# MCXC444 register map
Vendor: NXP Semiconductors; Series: MCX; File version: 1.6
CPU: CM0PLUS r0p0, little endian, no MPU, no FPU, VTOR, 2 interrupt priority bits
Registers are 32-bit, read-write, reset 0x0 unless marked. A register's access mark holds for its fields unless they carry their own. Offsets are from the block's base; [hi:lo] are bit positions; {n}, {i} and the like mark numbered series.

## GPIOA — General Purpose Input/Output
Base 0x400FF000; register names take the prefix GPIOA_
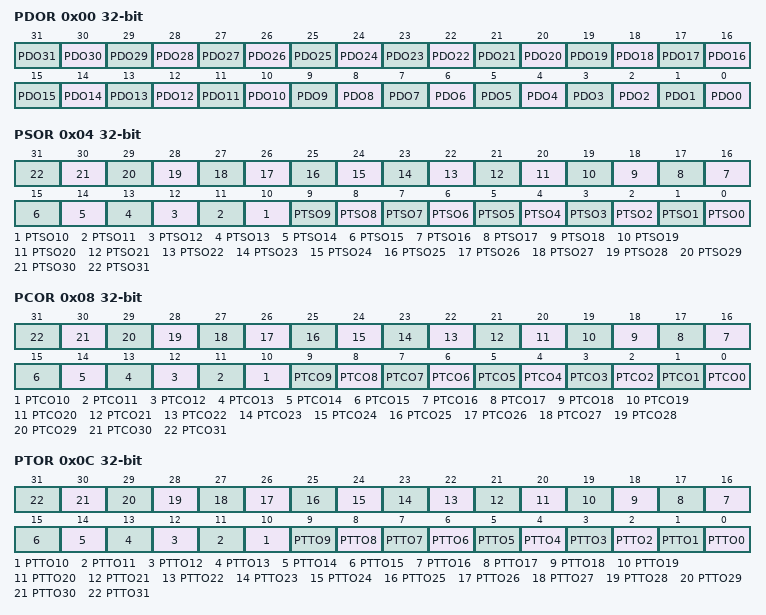
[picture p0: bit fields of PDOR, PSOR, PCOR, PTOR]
0x00 PDOR — Port Data Output Register
  [all] fields
    0=b00000000000000000000000000000000 (Logic level 0 is driven on pin, provided pin is configured for general-purpose output.); 1=b00000000000000000000000000000001 (Logic level 1 is driven on pin, provided pin is configured for general-purpose output.)
  [n] PDO{n} (n=0..31) — Port Data Output
0x04 PSOR — Port Set Output Register
  [all] fields
    0=b00000000000000000000000000000000 (Corresponding bit in PDORn does not change.); 1=b00000000000000000000000000000001 (Corresponding bit in PDORn is set to logic 1.)
  [n] PTSO{n} (n=0..31) — Port Set Output
0x08 PCOR — Port Clear Output Register
  [all] fields
    0=b00000000000000000000000000000000 (Corresponding bit in PDORn does not change.); 1=b00000000000000000000000000000001 (Corresponding bit in PDORn is cleared to logic 0.)
  [n] PTCO{n} (n=0..31) — Port Clear Output
0x0C PTOR — Port Toggle Output Register
  [all] fields
    0=b00000000000000000000000000000000 (Corresponding bit in PDORn does not change.); 1=b00000000000000000000000000000001 (Corresponding bit in PDORn is set to the inverse of its existing logic state.)
  [n] PTTO{n} (n=0..31) — Port Toggle Output
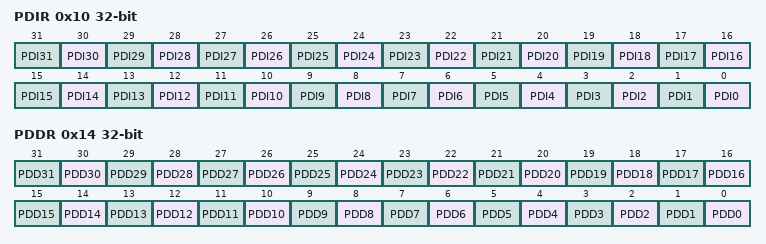
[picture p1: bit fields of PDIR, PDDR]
0x10 PDIR ro — Port Data Input Register
  [all] fields
    0=b00000000000000000000000000000000 (Pin logic level is logic 0, or is not configured for use by digital function.); 1=b00000000000000000000000000000001 (Pin logic level is logic 1.)
  [n] PDI{n} (n=0..31) — Port Data Input
0x14 PDDR — Port Data Direction Register
  [all] fields
    0=b00000000000000000000000000000000 (Pin is configured as general-purpose input, for the GPIO function.); 1=b00000000000000000000000000000001 (Pin is configured as general-purpose output, for the GPIO function.)
  [n] PDD{n} (n=0..31) — Port Data Direction

## GPIOB — General Purpose Input/Output
Base 0x400FF040; register names take the prefix GPIOB_
Registers as GPIOA.

## GPIOC — General Purpose Input/Output
Base 0x400FF080; register names take the prefix GPIOC_
Registers as GPIOA.

## GPIOD — General Purpose Input/Output
Base 0x400FF0C0; register names take the prefix GPIOD_
Registers as GPIOA.

## GPIOE — General Purpose Input/Output
Base 0x400FF100; register names take the prefix GPIOE_
Registers as GPIOA.

## SysTick — System timer
Base 0xE000E010; register names take the prefix SYST_
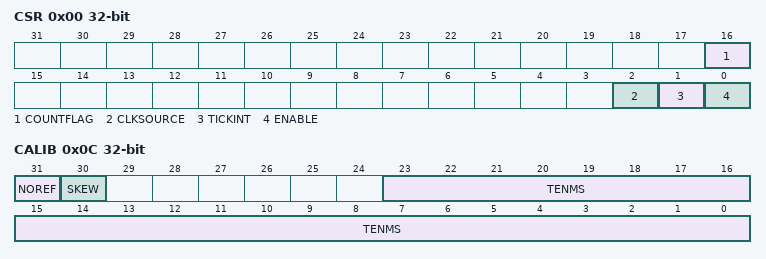
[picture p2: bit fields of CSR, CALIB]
0x00 CSR — SysTick Control and Status Register
  [16] COUNTFLAG
  [2] CLKSOURCE
    0=b0 (external clock); 1=b1 (processor clock)
  [1] TICKINT
    0=b0 (counting down to 0 does not assert the SysTick exception request); 1=b1 (counting down to 0 asserts the SysTick exception request)
  [0] ENABLE
    0=b0 (counter disabled); 1=b1 (counter enabled)
0x04 RVR — SysTick Reload Value Register
  [23:0] RELOAD — Value to load into the SysTick Current Value Register when the counter reaches 0
0x08 CVR — SysTick Current Value Register
  [23:0] CURRENT — Current value at the time the register is accessed
0x0C CALIB ro — SysTick Calibration Value Register
  [31] NOREF
    0=b0 (The reference clock is provided); 1=b1 (The reference clock is not provided)
  [30] SKEW
    0=b0 (10ms calibration value is exact); 1=b1 (10ms calibration value is inexact, because of the clock frequency)
  [23:0] TENMS — Reload value to use for 10ms timing

## MTB — Micro Trace Buffer
Base 0xF0000000; register names take the prefix MTB_
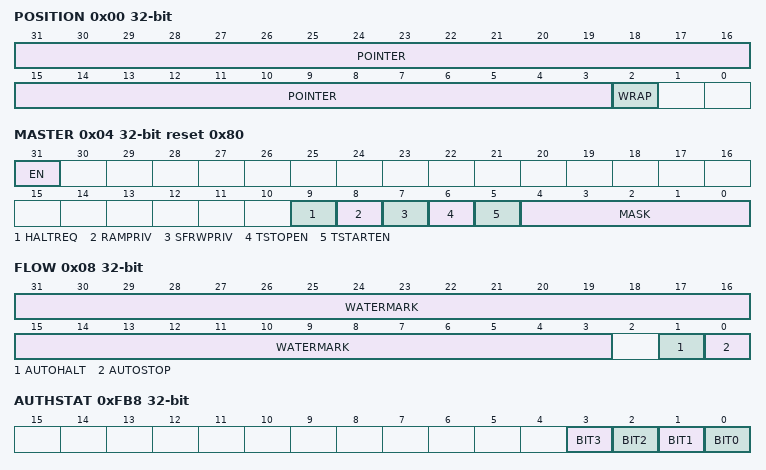
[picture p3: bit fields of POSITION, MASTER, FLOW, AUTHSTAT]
0x00 POSITION (reset mask 0x3) — MTB Position Register
  [31:3] POINTER — Trace Packet Address Pointer[28:0]
  [2] WRAP
0x04 MASTER reset 0x80 (reset mask 0xFFFFFFE0) — MTB Master Register
  [31] EN — Main Trace Enable
  [9] HALTREQ — Halt Request
  [8] RAMPRIV — RAM Privilege
  [7] SFRWPRIV — Special Function Register Write Privilege
  [6] TSTOPEN — Trace Stop Input Enable
  [5] TSTARTEN — Trace Start Input Enable
  [4:0] MASK
0x08 FLOW (reset mask 0x4) — MTB Flow Register
  [31:3] WATERMARK — WATERMARK[28:0]
  [1] AUTOHALT
  [0] AUTOSTOP
0x0C BASE ro reset not defined — MTB Base Register
  [31:0] BASEADDR
0xF00 MODECTRL ro — Integration Mode Control Register
0xFA0 TAGSET ro — Claim TAG Set Register
0xFA4 TAGCLEAR ro — Claim TAG Clear Register
0xFB0 LOCKACCESS ro
  [31:0] LOCKACCESS — Hardwired to 0x0000_0000
0xFB4 LOCKSTAT ro — Lock Status Register
0xFB8 AUTHSTAT ro — Authentication Status Register
  [3] BIT3
  [2] BIT2
  [1] BIT1
  [0] BIT0 — Connected to DBGEN.
0xFBC DEVICEARCH ro reset 0x47700A31 — Device Architecture Register
0xFC8 DEVICECFG ro — Device Configuration Register
0xFCC DEVICETYPID ro reset 0x31 — Device Type Identifier Register
0xFD0 PERIPHID{x} (x=4,5,6,7,0,1,2,3; step 0x4) ro reset not defined — Peripheral ID Register
  [31:0] PERIPHID
{0xFF0+4i} COMPID{i} (i=0..3) ro reset not defined — Component ID Register
  [31:0] COMPID — Component ID
